# ATSAMD21G17L register map
Vendor: Microchip Technology Inc.; Series: SAMD21; File version: G
CPU: CM0+ r0p1, little endian, no MPU, no FPU, VTOR, 2 interrupt priority bits, 30 interrupts
Registers are 32-bit, read-write, reset 0x0 unless marked. A register's access mark holds for its fields unless they carry their own. Offsets are from the block's base; [hi:lo] are bit positions; lines under a group give offsets from that group; {n}, {i} and the like mark numbered series; 'fields as' and 'values as' point back to an identical list.

## RTC — Real-Time Counter
Base 0x40001400; register names take the prefix RTC_
0x00 MODE0 group — 32-bit Counter with Single 32-bit Compare
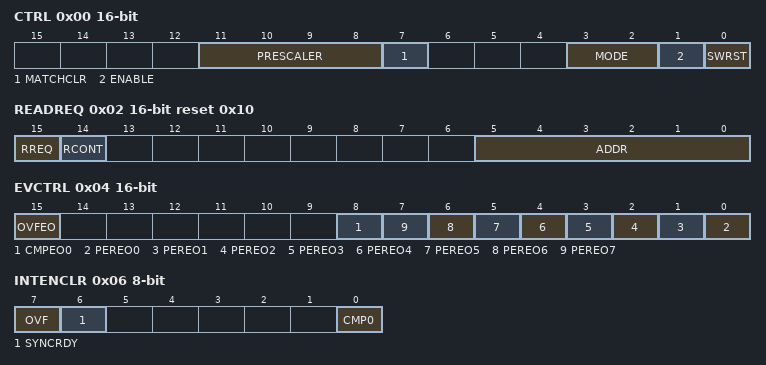
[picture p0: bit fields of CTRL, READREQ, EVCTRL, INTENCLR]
  0x00 CTRL 16-bit — MODE0 Control
    [11:8] PRESCALER
      0=DIV1 (CLK_RTC_CNT = GCLK_RTC/1); 1=DIV2 (CLK_RTC_CNT = GCLK_RTC/2); 2=DIV4 (CLK_RTC_CNT = GCLK_RTC/4); 3=DIV8 (CLK_RTC_CNT = GCLK_RTC/8); 4=DIV16 (CLK_RTC_CNT = GCLK_RTC/16); 5=DIV32 (CLK_RTC_CNT = GCLK_RTC/32); 6=DIV64 (CLK_RTC_CNT = GCLK_RTC/64); 7=DIV128 (CLK_RTC_CNT = GCLK_RTC/128); 8=DIV256 (CLK_RTC_CNT = GCLK_RTC/256); 9=DIV512 (CLK_RTC_CNT = GCLK_RTC/512); 10=DIV1024 (CLK_RTC_CNT = GCLK_RTC/1024)
    [7] MATCHCLR — Clear on Match
    [3:2] MODE — Operating Mode
      0=COUNT32 (Mode 0: 32-bit Counter); 1=COUNT16 (Mode 1: 16-bit Counter); 2=CLOCK (Mode 2: Clock/Calendar)
    [1] ENABLE
    [0] SWRST wo write-1-sets — Software Reset
  0x02 READREQ 16-bit reset 0x10 — Read Request
    [15] RREQ wo write-1-sets — Read Request
    [14] RCONT — Read Continuously
    [5:0] ADDR ro — Address
  0x04 EVCTRL 16-bit — MODE0 Event Control
    [15] OVFEO — Overflow Event Output Enable
    [8] CMPEO0 — Compare 0 Event Output Enable
    [n] PEREO{n} (n=0..7) — Periodic Interval {n} Event Output Enable
  0x06 INTENCLR 8-bit — MODE0 Interrupt Enable Clear
    [7] OVF — Overflow Interrupt Enable
    [6] SYNCRDY — Synchronization Ready Interrupt Enable
    [0] CMP0 — Compare 0 Interrupt Enable
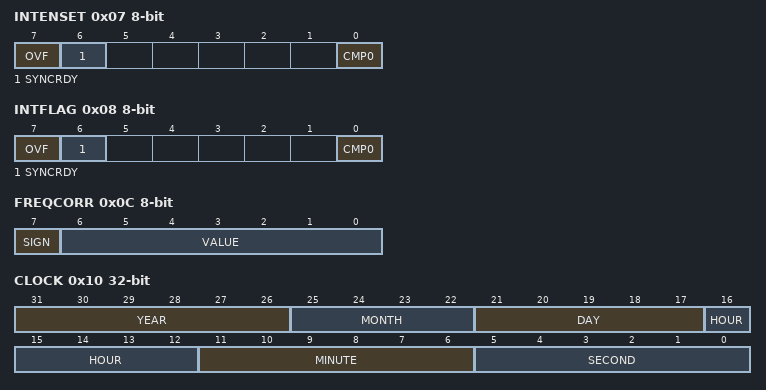
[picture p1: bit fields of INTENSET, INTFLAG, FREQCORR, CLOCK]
  0x07 INTENSET 8-bit — MODE0 Interrupt Enable Set
    fields as MODE0.INTENCLR
  0x08 INTFLAG 8-bit — MODE0 Interrupt Flag Status and Clear
    [7] OVF write-1-clears — Overflow
    [6] SYNCRDY write-1-clears — Synchronization Ready
    [0] CMP0 write-1-clears — Compare 0
  0x0A STATUS 8-bit
    [7] SYNCBUSY ro — Synchronization Busy
  0x0B DBGCTRL 8-bit — Debug Control
    [0] DBGRUN — Run During Debug
  0x0C FREQCORR 8-bit — Frequency Correction
    [7] SIGN — Correction Sign
    [6:0] VALUE — Correction Value
  0x10 COUNT — MODE0 Counter Value
    [31:0] COUNT — Counter Value
  {0x18+4j} COMP{j} (j=0..0) — MODE0 Compare n Value
    [31:0] COMP — Compare Value
0x00 MODE1 group (alternate view of MODE0) — 16-bit Counter with Two 16-bit Compares
  0x00 CTRL 16-bit — MODE1 Control
    [11:8] PRESCALER
      values as MODE0.CTRL.PRESCALER
    [3:2] MODE — Operating Mode
      values as MODE0.CTRL.MODE
    [1] ENABLE
    [0] SWRST wo write-1-sets — Software Reset
  0x02 READREQ 16-bit reset 0x10 — Read Request
    fields as MODE0.READREQ
  0x04 EVCTRL 16-bit — MODE1 Event Control
    [15] OVFEO — Overflow Event Output Enable
    [9] CMPEO1 — Compare 1 Event Output Enable
    [8] CMPEO0 — Compare 0 Event Output Enable
    [n] PEREO{n} (n=0..7) — Periodic Interval {n} Event Output Enable
  0x06 INTENCLR 8-bit — MODE1 Interrupt Enable Clear
    [7] OVF — Overflow Interrupt Enable
    [6] SYNCRDY — Synchronization Ready Interrupt Enable
    [1] CMP1 — Compare 1 Interrupt Enable
    [0] CMP0 — Compare 0 Interrupt Enable
  0x07 INTENSET 8-bit — MODE1 Interrupt Enable Set
    fields as MODE1.INTENCLR
  0x08 INTFLAG 8-bit — MODE1 Interrupt Flag Status and Clear
    [7] OVF write-1-clears — Overflow
    [6] SYNCRDY write-1-clears — Synchronization Ready
    [1] CMP1 write-1-clears — Compare 1
    [0] CMP0 write-1-clears — Compare 0
  0x0A STATUS 8-bit
    [7] SYNCBUSY ro — Synchronization Busy
  0x0B DBGCTRL 8-bit — Debug Control
    [0] DBGRUN — Run During Debug
  0x0C FREQCORR 8-bit — Frequency Correction
    [7] SIGN — Correction Sign
    [6:0] VALUE — Correction Value
  0x10 COUNT 16-bit — MODE1 Counter Value
    [15:0] COUNT — Counter Value
  0x14 PER 16-bit — MODE1 Counter Period
    [15:0] PER — Counter Period
  {0x18+2j} COMP{j} (j=0..1) 16-bit — MODE1 Compare n Value
    [15:0] COMP — Compare Value
0x00 MODE2 group (alternate view of MODE0) — Clock/Calendar with Alarm
  0x00 CTRL 16-bit — MODE2 Control
    [11:8] PRESCALER
      values as MODE0.CTRL.PRESCALER
    [7] MATCHCLR — Clear on Match
    [6] CLKREP — Clock Representation
    [3:2] MODE — Operating Mode
      values as MODE0.CTRL.MODE
    [1] ENABLE
    [0] SWRST wo write-1-sets — Software Reset
  0x02 READREQ 16-bit reset 0x10 — Read Request
    fields as MODE0.READREQ
  0x04 EVCTRL 16-bit — MODE2 Event Control
    [15] OVFEO — Overflow Event Output Enable
    [8] ALARMEO0 — Alarm 0 Event Output Enable
    [n] PEREO{n} (n=0..7) — Periodic Interval {n} Event Output Enable
  0x06 INTENCLR 8-bit — MODE2 Interrupt Enable Clear
    [7] OVF — Overflow Interrupt Enable
    [6] SYNCRDY — Synchronization Ready Interrupt Enable
    [0] ALARM0 — Alarm 0 Interrupt Enable
  0x07 INTENSET 8-bit — MODE2 Interrupt Enable Set
    fields as MODE2.INTENCLR
  0x08 INTFLAG 8-bit — MODE2 Interrupt Flag Status and Clear
    [7] OVF write-1-clears — Overflow
    [6] SYNCRDY write-1-clears — Synchronization Ready
    [0] ALARM0 write-1-clears
  0x0A STATUS 8-bit
    [7] SYNCBUSY ro — Synchronization Busy
  0x0B DBGCTRL 8-bit — Debug Control
    [0] DBGRUN — Run During Debug
  0x0C FREQCORR 8-bit — Frequency Correction
    [7] SIGN — Correction Sign
    [6:0] VALUE — Correction Value
  0x10 CLOCK — MODE2 Clock Value
    [31:26] YEAR
    [25:22] MONTH
    [21:17] DAY
    [16:12] HOUR
      0=AM (AM when CLKREP in 12-hour); 16=PM (PM when CLKREP in 12-hour)
    [11:6] MINUTE
    [5:0] SECOND
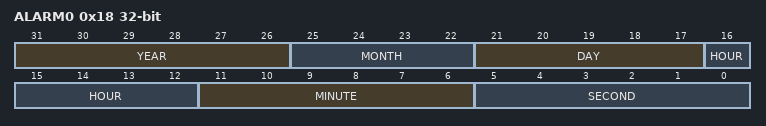
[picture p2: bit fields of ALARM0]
  {0x18+8j} ALARM{j} (j=0..0) — MODE2 Alarm n Value
    [31:26] YEAR
    [25:22] MONTH
    [21:17] DAY
    [16:12] HOUR
      0=AM (Morning hour); 16=PM (Afternoon hour)
    [11:6] MINUTE
    [5:0] SECOND
  {0x1C+8j} MASK{j} (j=0..0) 8-bit — MODE2 Alarm n Mask
    [2:0] SEL — Alarm Mask Selection
      0=OFF (Alarm Disabled); 1=SS (Match seconds only); 2=MMSS (Match seconds and minutes only); 3=HHMMSS (Match seconds, minutes, and hours only); 4=DDHHMMSS (Match seconds, minutes, hours, and days only); 5=MMDDHHMMSS (Match seconds, minutes, hours, days, and months only); 6=YYMMDDHHMMSS (Match seconds, minutes, hours, days, months, and years)
